# APM32F411 register map
Vendor: Geehy; File version: 2024.11.05
CPU: CM4 r1p0, little endian, 3 interrupt priority bits
Registers are 32-bit, read-write, reset 0x0 unless marked. A register's access mark holds for its fields unless they carry their own. Offsets are from the block's base; [hi:lo] are bit positions; lines under a group give offsets from that group; {n}, {i} and the like mark numbered series.

## SCB — System Control Block
Base 0xE000ED00
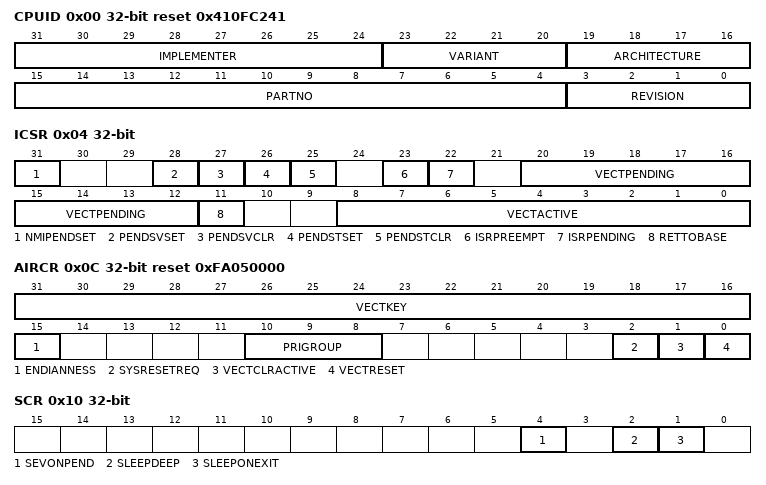
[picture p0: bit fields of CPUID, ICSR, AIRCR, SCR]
0x00 CPUID ro reset 0x410FC241 — Provides identification information for the processor
  [31:24] IMPLEMENTER — Implementer identification
  [23:20] VARIANT — Processor variant number
  [19:16] ARCHITECTURE — Indicates the architecture version
  [15:4] PARTNO — Part number of the processor
  [3:0] REVISION — Processor revision number
0x04 ICSR — Interrupt Control and State Register
  [31] NMIPENDSET — NMI set-pending bit
  [28] PENDSVSET — Set PendSV exception pending bit
  [27] PENDSVCLR — Clear PendSV exception pending bit
  [26] PENDSTSET — Set SysTick exception pending bit
  [25] PENDSTCLR — Clear SysTick exception pending bit
  [23] ISRPREEMPT — Indicates if a pending interrupt is preempting the current active interrupt
  [22] ISRPENDING — Indicates if an interrupt is pending
  [20:12] VECTPENDING — Exception number of the pending interrupt
  [11] RETTOBASE — Indicates return to base level
  [8:0] VECTACTIVE — Active exception number
0x08 VTOR — Vector Table Offset Register
  [31:7] TBLOFF — Vector table offset in memory
0x0C AIRCR reset 0xFA050000 (reset mask 0xFFFF7FFF) — Application Interrupt and Reset Control Register
  [31:16] VECTKEY — Register writes must write 0x05FA to this field, otherwise the write is ignored. On reads, returns 0xFA05.
  [15] ENDIANNESS — Data endianness (0: little-endian, 1: big-endian)
  [10:8] PRIGROUP — Priority group field
  [2] SYSRESETREQ — Requests a system reset
  [1] VECTCLRACTIVE — Clear all active state information for exceptions
  [0] VECTRESET — System Reset Request
0x10 SCR (reset mask 0x7) — System Control Register
  [4] SEVONPEND — Send Event on Pending
  [2] SLEEPDEEP — Controls deep sleep behavior
  [1] SLEEPONEXIT — Indicates sleep-on-exit behavior
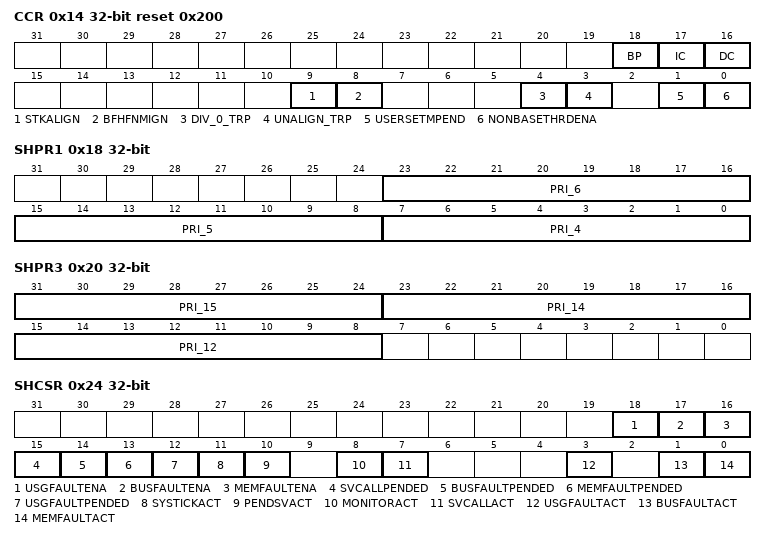
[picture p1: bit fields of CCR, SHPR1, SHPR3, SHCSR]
0x14 CCR reset 0x200 (reset mask 0x3FFF) — Configuration and Control Register
  [18] BP — Branch prediction enable
  [17] IC — Instruction cache enable
  [16] DC — Data cache enable
  [9] STKALIGN — Indicates 8-byte stack alignment on exception entry
  [8] BFHFNMIGN — Ignore BusFault in NMI and HardFault handlers
  [4] DIV_0_TRP — Enable trap for divide-by-zero
  [3] UNALIGN_TRP — Enable trap for unaligned accesses
  [1] USERSETMPEND — Allow user-level write to the Software Trigger Interrupt Register
  [0] NONBASETHRDENA — Enable non-base thread mode
0x18 SHPR1 — System Handler Priority Register 1
  [23:16] PRI_6 — Priority of system handler 6 (Usage Fault)
  [15:8] PRI_5 — Priority of system handler 5 (Bus Fault)
  [7:0] PRI_4 — Priority of system handler 4 (Memory Management)
0x1C SHPR2 — System Handler Priority Register 2
  [31:24] PRI_11 — Priority of system handler 11 (SVCall)
0x20 SHPR3 — System Handler Priority Register 3
  [31:24] PRI_15 — Priority of system handler 15 (SysTick)
  [23:16] PRI_14 — Priority of system handler 14 (PendSV)
  [15:8] PRI_12 — Priority of system handler 12 (Debug Monitor)
0x24 SHCSR — System Handler Control and State Register
  [18] USGFAULTENA — Enables the Usage Fault handler
  [17] BUSFAULTENA — Enables the Bus Fault handler
  [16] MEMFAULTENA — Enables the Memory Management Fault handler
  [15] SVCALLPENDED — Indicates pending state of the SVCall handler
  [14] BUSFAULTPENDED — Indicates pending state of the Bus Fault handler
  [13] MEMFAULTPENDED — Indicates pending state of the Memory Management Fault handler
  [12] USGFAULTPENDED — Indicates pending state of the Usage Fault handler
  [11] SYSTICKACT — Indicates active state of the SysTick handler
  [10] PENDSVACT — Indicates active state of the PendSV handler
  [8] MONITORACT — Indicates active state of the Debug Monitor handler
  [7] SVCALLACT — Indicates active state of the SVCall handler
  [3] USGFAULTACT — Indicates active state of the Usage Fault handler
  [1] BUSFAULTACT — Indicates active state of the Bus Fault handler
  [0] MEMFAULTACT — Indicates active state of the Memory Management Fault handler
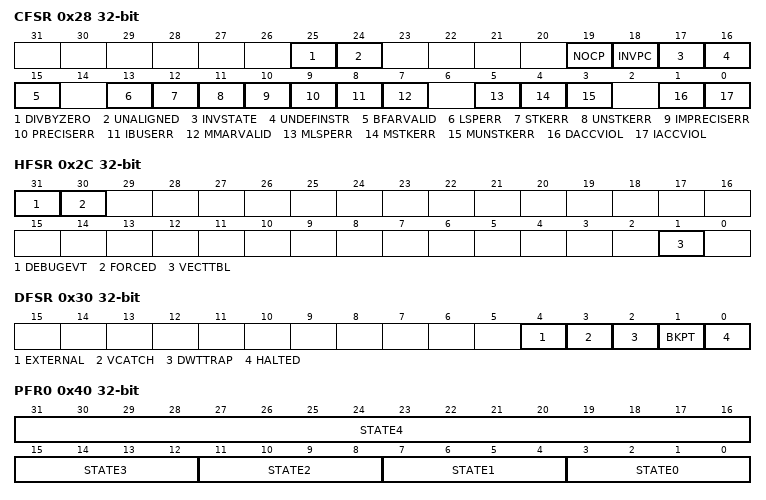
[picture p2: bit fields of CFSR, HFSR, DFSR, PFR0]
0x28 CFSR — Configurable Fault Status Register
  [25] DIVBYZERO — Divide by zero usage fault
  [24] UNALIGNED — Unaligned access usage fault
  [19] NOCP — No coprocessor usage fault
  [18] INVPC — Invalid program counter usage fault
  [17] INVSTATE — Invalid state usage fault
  [16] UNDEFINSTR — Undefined instruction usage fault
  [15] BFARVALID — Indicates the BFAR holds a valid fault address
  [13] LSPERR — Lazy state preservation error
  [12] STKERR — Stacking error during exception entry
  [11] UNSTKERR — Unstacking error during exception return
  [10] IMPRECISERR — Imprecise data bus error
  [9] PRECISERR — Precise data bus error
  [8] IBUSERR — Instruction bus error
  [7] MMARVALID — Indicates the MMAR holds a valid fault address
  [5] MLSPERR — Lazy state preservation error
  [4] MSTKERR — Stacking error during exception entry
  [3] MUNSTKERR — Unstacking error during exception return
  [1] DACCVIOL — Data access violation
  [0] IACCVIOL — Instruction access violation
0x2C HFSR — HardFault Status Register
  [31] DEBUGEVT — Indicates a HardFault triggered by a debug event
  [30] FORCED — Indicates a forced HardFault has occurred
  [1] VECTTBL — Indicates a vector table read fault has occurred
0x30 DFSR — Debug Fault Status Register
  [4] EXTERNAL — Indicates an external debug request has occurred
  [3] VCATCH — Indicates a vector catch debug event has occurred
  [2] DWTTRAP — Indicates a data watchpoint and trace (DWT) debug event has occurred
  [1] BKPT — Indicates a breakpoint debug event has occurred
  [0] HALTED — Indicates a halt request debug event has occurred
0x34 MMFAR — Memory Management Fault Address Register
  [31:0] ADDRESS — Fault address causing the memory management fault
0x38 BFAR — Bus Fault Address Register
  [31:0] ADDRESS — Fault address causing the bus fault
0x3C AFSR — Auxiliary Fault Status Register
  [31:0] IMPDEF — Implementation defined auxiliary fault status
0x40 PFR0 ro — Processor Feature Register 0
  [31:16] STATE4 — Reserved, must be zero
  [15:12] STATE3 — Reserved, must be zero
  [11:8] STATE2 — Reserved, must be zero
  [7:4] STATE1 — Indicates support for the Armv6-M architecture
  [3:0] STATE0 — Indicates support for the Armv7-M architecture
0x44 PFR1 ro — Processor Feature Register 1
0x48 DFR ro — Debug Feature Register
0x4C AFR ro — Auxiliary Feature Register
{0x50+4i} MMFR{i} ro (i=0..3) — Memory Model Feature Register {i}
{0x60+4i} ISAR{i} ro (i=0..5) — Instruction Set Attribute Register {i}
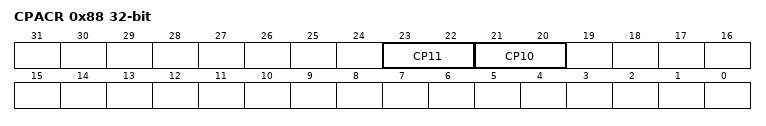
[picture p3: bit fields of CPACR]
0x88 CPACR — Coprocessor Access Control Register
  [23:22] CP11 — Access privileges for coprocessor 11 (floating-point unit)
  [21:20] CP10 — Access privileges for coprocessor 10 (floating-point unit)
